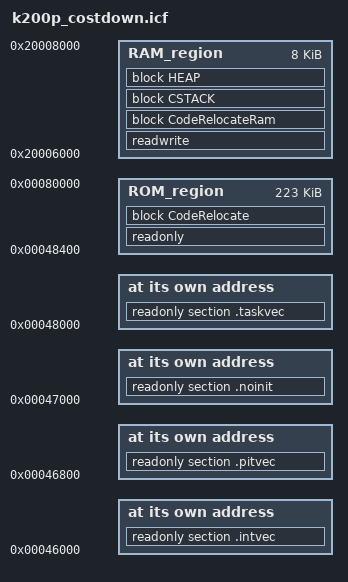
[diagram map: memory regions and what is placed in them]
/*###ICF### Section handled by ICF editor, don't touch! ****/
/*-Editor annotation file-*/
/* IcfEditorFile="$TOOLKIT_DIR$\config\ide\IcfEditor\cortex_v1_0.xml" */
/*-Specials-*/
define symbol __ICFEDIT_intvec_start__ = 0x00046000;
/*-Memory Regions-*/
define symbol __ICFEDIT_region_ROM_start__ = 0x00046000;
define symbol __ICFEDIT_region_ROM_end__   = 0x00080000;//0x00078000;

define symbol __ICFEDIT_region_RAM_start__ = 0x20006000;
define symbol __ICFEDIT_region_RAM_end__   = 0x20008000;

//define symbol __ICFEDIT_region_RAM2_start__ = 0x60900000;
//define symbol __ICFEDIT_region_RAM2_end__   = 0x60a00000;

/*-Sizes-*/
define symbol __ICFEDIT_size_cstack__ = 0x100;
define symbol __ICFEDIT_size_heap__   = 0x1;
/**** End of ICF editor section. ###ICF###*/

//define exported symbol __VECTOR_TABLE            = __ICFEDIT_intvec_start__;
//define exported symbol __VECTOR_RAM              = __ICFEDIT_region_RAM_start__;

//define exported symbol __PIT_VECTOR_TABLE        = __ICFEDIT_intvec_start__+0x800;
//define exported symbol __BOOT_STACK_ADDRESS      = __ICFEDIT_region_RAM_end__ - 8;


define symbol __pit_start__                      = __ICFEDIT_intvec_start__ + 0x800;
define symbol __code_start__                     = __ICFEDIT_intvec_start__ + 0x1000;
define symbol __task_start__                     = __ICFEDIT_intvec_start__ + 0x2000;

define memory mem with size                      = 4G;
define region ROM_region                         = mem:[from __ICFEDIT_region_ROM_start__ +0x2400  to __ICFEDIT_region_ROM_end__];
define region RAM_region                         = mem:[from __ICFEDIT_region_RAM_start__   to __ICFEDIT_region_RAM_end__];
//define region RAM2_region                        = mem:[from __ICFEDIT_region_RAM2_start__  to __ICFEDIT_region_RAM2_end__];

define block CSTACK    with alignment = 8, size = __ICFEDIT_size_cstack__   { };
define block HEAP      with alignment = 8, size = __ICFEDIT_size_heap__     { };

initialize manually { readwrite };
initialize manually { section .data};
initialize manually { section .textrw };
do not initialize  { section .noinit };

define block CodeRelocate { section .textrw_init };
define block CodeRelocateRam { section .textrw };


place at address mem:__ICFEDIT_intvec_start__ { readonly section .intvec };
place at address mem:__pit_start__ { readonly section .pitvec };
place at address mem:__task_start__ { readonly section .taskvec };
place at address mem:__code_start__ { readonly section .noinit};

place in ROM_region   { readonly, block CodeRelocate };

place in RAM_region   {readwrite, block CodeRelocateRam,
                        block CSTACK, block HEAP };
                    
